# A31G12x_series register map
Vendor: ABOV Semiconductor Co., Ltd.; Series: A31G12x_series; File version: 1.0
CPU: CM0PLUS r0p1, little endian, no MPU, no FPU, VTOR, 2 interrupt priority bits
Registers are 32-bit, read-write, reset 0x0 unless marked. A register's access mark holds for its fields unless they carry their own. Offsets are from the block's base; [hi:lo] are bit positions; {n}, {i} and the like mark numbered series.

## USART10 — USART 10 (UART + SPI)
Base 0x40003800
Same registers: USART12 0x40003A00, USART13 0x40003B00
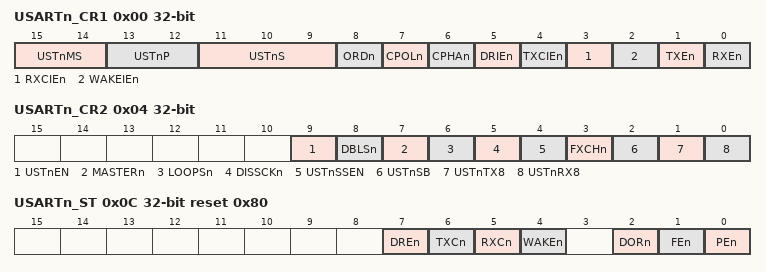
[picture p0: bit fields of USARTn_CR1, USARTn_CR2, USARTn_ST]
0x00 USARTn_CR1 — USARTn Control Register 1
  [15:14] USTnMS — USARTn Operation Mode Selection bits
    0=ASYNC (Asynchronous Mode (UART)); 1=SYNC (Synchronous Mode); 3=SPI (SPI mode)
  [13:12] USTnP — Selects Parity Generation and Check method (only UART mode)
    0=NO_PARITY; 2=EVEN (Even parity); 3=ODD (Odd parity)
  [11:9] USTnS — Selects the length of data bit in a frame when Asynchronous or Synchronous mode
    {v}={v+5}BIT (v=0..3); 7=9BIT
  [8] ORDn — Selects the first data bit to be transmitted (only SPI mode)
    0=LSB_FIRST; 1=MSB_FIRST
  [7] CPOLn — Selects the clock polarity of ACK in synchronous or SPI mode
    0=CHANGE_AT_FALLING_EDGE (TXD Change @Rising Edge, RXD Change @Falling Edge); 1=CHANGE_AT_RISING_EDGE (TXD Change @Falling Edge, RXD Change @Rising Edge)
  [6] CPHAn — (null)The CPOLn and this bit determine if data are sampled on the leading or trailing edge of SCK (only SPI mode)
    0=SPL_STP (Sample / Setup); 1=STP_SPL (Setup / Sample)
  [5] DRIEn — Transmit Data Register Empty Interrupt Enable bit
  [4] TXCIEn — Transmit Complete Interrupt Enable bit
  [3] RXCIEn — Receive Complete Interrupt Enable bit
  [2] WAKEIEn — Asynchronous Wake-up Interrupt Enable bit in Deep Sleep Mode. When device is in deep sleep mode, if RXD goes to low level, an interrupt can be requested to wake-up system (only UART mode)
  [1] TXEn — Enables the Transmitter unit
  [0] RXEn — enabled [0] RXEn Enables the Receiver unit
0x04 USARTn_CR2 — USARTn Control Register 2
  [9] USTnEN — (nActivate USARTn Block by supplyingull)
  [8] DBLSn — Selects receiver sampling rate (only UART mode)
  [7] MASTERn — Selects master or slave in SPI or Synchronous mode and controls the direction of SCK pin
  [6] LOOPSn — Control the Loop Back mode of USARTn for test mode
  [5] DISSCKn — In synchronous mode operation, selects the waveform of SCK output
  [4] USTnSSEN — This bit controls the SS pin operation (only SPI mode)
  [3] FXCHn — SPI port function exchange control bit (only SPI mode)
  [2] USTnSB — Selects the length of stop bit in Asynchronous or Synchronous mode
  [1] USTnTX8 — The ninth bit of data frame in Asynchronous or Synchronous mode of operation. Write this bit first before loading the USTnDR register
  [0] USTnRX8 — The ninth bit of data frame in Asynchronous or Synchronous mode of operation. Read this bit first before reading the receive buffer (only UART mode)
0x0C USARTn_ST reset 0x80 — USARTn Status Register
  [7] DREn — Transmit Data Register Empty Interrupt Flag
  [6] TXCn — Transmit Complete Interrupt Flag
  [5] RXCn ro — Receive Complete Interrupt Flag
  [4] WAKEn — Asynchronous Wake-up Interrupt Flag
  [2] DORn ro — This bit is set if data OverRun occurs
  [1] FEn — This bit is set if the first stop bit of next character in the receive buffer is detected as '0'. This bit is valid until the receive buffer is read (only UART mode)
  [0] PEn — This bit is set if the next character in the receive buffer has a Parity Error while parity is checked. This bit is valid until the receive buffer is read (only UART mode)
0x10 USARTn_BDR reset 0xFFF — USARTn Baud Rate Generation Register
  [11:0] BDATA — The value in this register is used to generate internal baud rate in UART mode or to generate SCK clock in SPI mode. To prevent malfunction, do not write '0' in UART mode and do not write '0' or '1' in synchronous or SPI mode.
0x14 USARTn_DR — USARTn Data Register
  [7:0] DATA — The USART Transmit buffer and Receive buffer share the same I/O address with this DATA register. The Transmit Data Buffer is the destination for data written to the USTnDR register. Reading the USTnDR register returns the contents of the Receive Buffer. Write to this register only when the DRE flag is set. In SPI master mode, the SCK clock is generated when data are written to this register.

## USART11 — USART 11 (UART + SPI)
Base 0x40003900
Registers as USART10; these are added or differ:
? ?
